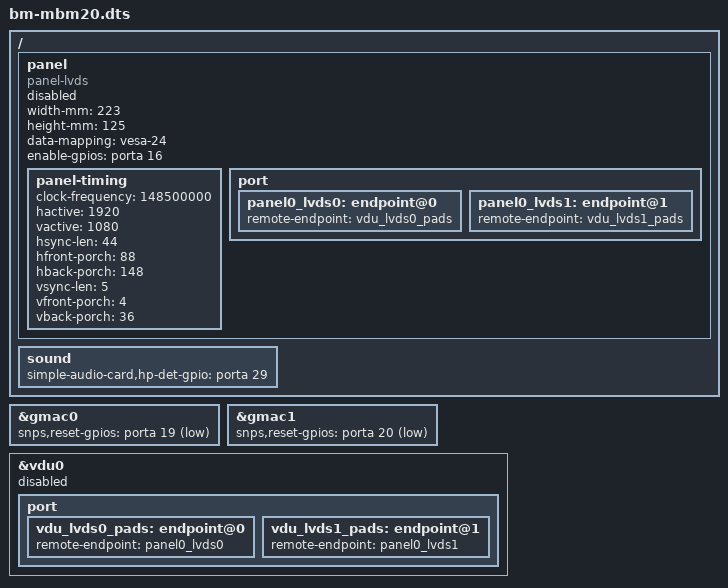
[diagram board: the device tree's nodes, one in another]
// SPDX-License-Identifier: GPL-2.0
/*
 * Device tree source for MBM20-compatible boards:
 *   - TF307-MB-S-D (BM1BM1-D)
 *
 * Copyright (C) 2021 Baikal Electronics, JSC
 */

/dts-v1/;

#include "bm-mbm.dtsi"

/ {
	panel {
		/* In order to utilize LVDS LCD panel,
		   set this to "okay" along with &vdu0 status property (see below). */
		status = "disabled";
		compatible = "panel-lvds";
		width-mm = <223>;
		height-mm = <125>;
		data-mapping = "vesa-24";
		enable-gpios = <&porta 16 GPIO_ACTIVE_HIGH>;
		panel-timing {
		// 1920x1080 @60Hz
			clock-frequency = <148500000>;
			hactive = <1920>;
			vactive = <1080>;
			hsync-len = <44>;
			hfront-porch = <88>;
			hback-porch = <148>;
			vsync-len = <5>;
			vfront-porch = <4>;
			vback-porch = <36>;
		};
		port {
			panel0_lvds0: endpoint@0 {
				remote-endpoint = <&vdu_lvds0_pads>;
			};
			panel0_lvds1: endpoint@1 {
				remote-endpoint = <&vdu_lvds1_pads>;
			};
		};
	};

	sound {
		simple-audio-card,hp-det-gpio = <&porta 29 GPIO_ACTIVE_HIGH>;
	};
};

&gmac0 {
	status = "okay";
	snps,reset-gpios = <&porta 19 GPIO_ACTIVE_LOW>;
};

&gmac1 {
	status = "okay";
	snps,reset-gpios = <&porta 20 GPIO_ACTIVE_LOW>;
};

&vdu0 {
	/* In order to utilize LVDS LCD panel,
	   set this to "okay" along with panel status property (see above). */
	status = "disabled";
	port {
		vdu_lvds0_pads: endpoint@0 {
			remote-endpoint = <&panel0_lvds0>;
		};
		vdu_lvds1_pads: endpoint@1 {
			remote-endpoint = <&panel0_lvds1>;
		};
	};
};
